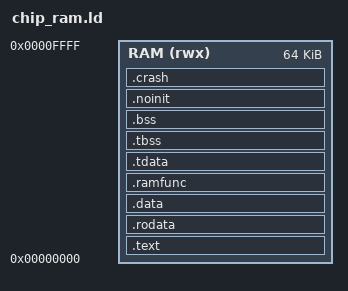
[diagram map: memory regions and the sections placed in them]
/* Generated by hw-proj — safe to edit outside the GENERATE zone */
/* Regenerate with: hw-proj gen linker */

/* hw-proj: GENERATE BEGIN */

/* Memory regions (memory.ld) */
INCLUDE memory.ld

/* RAM region over the system RAM */
/* ram: system RAM SRAM0 */
MEMORY
{
    RAM (rwx) : ORIGIN = 0x00000000, LENGTH = 0x10000
}

ENTRY(_start)

/* Flash image header */
SECTIONS
{
    PROVIDE(_bsp_trap = 0);
    __bsp_boot_vec = _bsp_trap;

/* Code and read-only data in the RAM */

    .text : ALIGN(16) {
        __copy_start = .;
        KEEP(*(.text.init))
        *(.text .text.*)
    } > RAM

    .rodata : ALIGN(16) {
        *(.rodata .rodata.* .srodata .srodata.*)
    } > RAM

/* Initialised data, RAM functions and the TLS template */

    .data : ALIGN(16) {
        *(.data .data.* .sdata .sdata.*)
    } > RAM

    .ramfunc : ALIGN(16) {
        *(.ramfunc .ramfunc.*)
    } > RAM

    .tdata : ALIGN(16) {
        __tdata_start = .;
        *(.tdata .tdata.*)
        . = ALIGN(8);
        __tdata_end = .;
    } > RAM
    __tdata_load = LOADADDR(.tdata);
    __copy_load = __copy_start;
    __copy_end = __copy_start;

/* Thread-local zero data and .bss */

    .tbss (NOLOAD) : {
        *(.tbss .tbss.*)
        *(.tcommon)
    } > RAM
    __tls_size = ALIGN(SIZEOF(.tdata) + SIZEOF(.tbss), 16);

    .bss (NOLOAD) : ALIGN(16) {
        __bss_start = .;
        *(.bss .bss.* .sbss .sbss.* COMMON)
        . = ALIGN(8);
        __bss_end = .;
    } > RAM

/* Words that survive a reset: .noinit */

    .noinit (NOLOAD) : ALIGN(16) {
        *(.noinit .noinit.*)
    } > RAM

/* Heap, first core's stack and the top block */

    . = ALIGN(16);
    _heap_start = .;
    __top_block = ORIGIN(RAM) + LENGTH(RAM) - 16;
    _sim_pass = __top_block;
    _sim_assert = __top_block + 4;
    _sim_spare0 = __top_block + 8;
    _sim_spare1 = __top_block + 12;
    __bsp_crash = __top_block - 0x20;          /* the crash record, BSP_CRASH in soc.h */
    .crash __bsp_crash (NOLOAD) : {
        . = . + 0x20;
    } > RAM
    __hart0_trap = __bsp_crash;               /* CORE0 */
    __hart0_sp = __hart0_trap - 0x100;
    __hart0_stack_lo = __hart0_sp - 0x800;
    __hart0_tls = __hart0_stack_lo - __tls_size;
    _heap_end = __hart0_tls;
    ASSERT(_heap_start <= __hart0_tls, "sections and stacks do not fit in the RAM (SRAM0)")
}

/* hw-proj: GENERATE END */

/* Your own sections and symbols go here, outside the zone: the zone is rewritten by every gen. */
